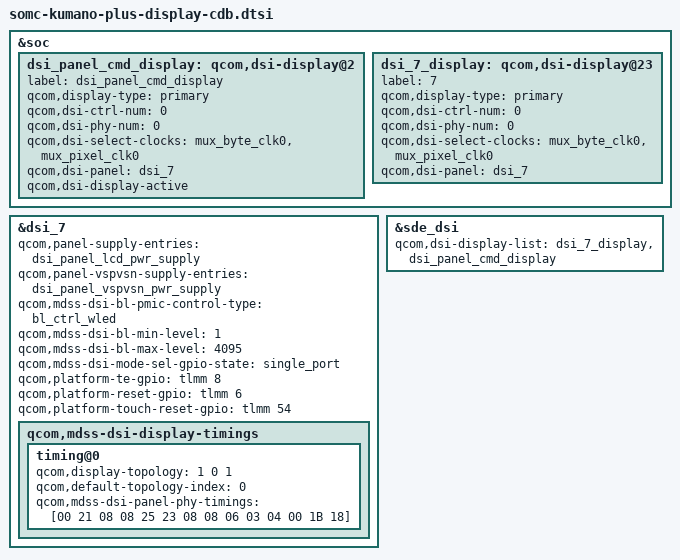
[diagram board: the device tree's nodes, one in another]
/* Copyright (c) 2015-2018, The Linux Foundation. All rights reserved.
 *
 * This program is free software; you can redistribute it and/or modify
 * it under the terms of the GNU General Public License version 2 and
 * only version 2 as published by the Free Software Foundation.
 *
 * This program is distributed in the hope that it will be useful,
 * but WITHOUT ANY WARRANTY; without even the implied warranty of
 * MERCHANTABILITY or FITNESS FOR A PARTICULAR PURPOSE.  See the
 * GNU General Public License for more details.
 */
#include "dsi-panel-akari.dtsi"

&soc {
	dsi_panel_cmd_display: qcom,dsi-display@2 {
		label = "dsi_panel_cmd_display";
		qcom,display-type = "primary";

		qcom,dsi-ctrl-num = <0>;
		qcom,dsi-phy-num = <0>;
		qcom,dsi-select-clocks = "mux_byte_clk0", "mux_pixel_clk0";

		qcom,dsi-panel = <&dsi_7>;
	};

	dsi_7_display: qcom,dsi-display@23 {
		label = "7";
		qcom,display-type = "primary";

		qcom,dsi-ctrl-num = <0>;
		qcom,dsi-phy-num = <0>;
		qcom,dsi-select-clocks = "mux_byte_clk0", "mux_pixel_clk0";

		qcom,dsi-panel = <&dsi_7>;
	};
};

&dsi_7 {
	qcom,panel-supply-entries = <&dsi_panel_lcd_pwr_supply>;
	qcom,panel-vspvsn-supply-entries = <&dsi_panel_vspvsn_pwr_supply>;
	qcom,mdss-dsi-bl-pmic-control-type = "bl_ctrl_wled";
	qcom,mdss-dsi-bl-min-level = <1>;
	qcom,mdss-dsi-bl-max-level = <4095>;
	qcom,mdss-dsi-mode-sel-gpio-state = "single_port";
	qcom,platform-te-gpio = <&tlmm 8 0>;
	qcom,platform-reset-gpio = <&tlmm 6 0>;
	qcom,platform-touch-reset-gpio = <&tlmm 54 0>;
	qcom,mdss-dsi-display-timings {
		timing@0 {
			qcom,display-topology = <1 0 1>;
			qcom,default-topology-index = <0>;
			qcom,mdss-dsi-panel-phy-timings = [00 21 08 08 25 23 08 08 06 03 04 00 1B 18];
		};
	};
};

&sde_dsi {
	qcom,dsi-display-list =
		<
		&dsi_7_display
		&dsi_panel_cmd_display
		>;
};

&dsi_panel_cmd_display {
	qcom,dsi-display-active;
};

